VERSION ""

NS_ :

BS_:

BU_: ECU1 ECU2

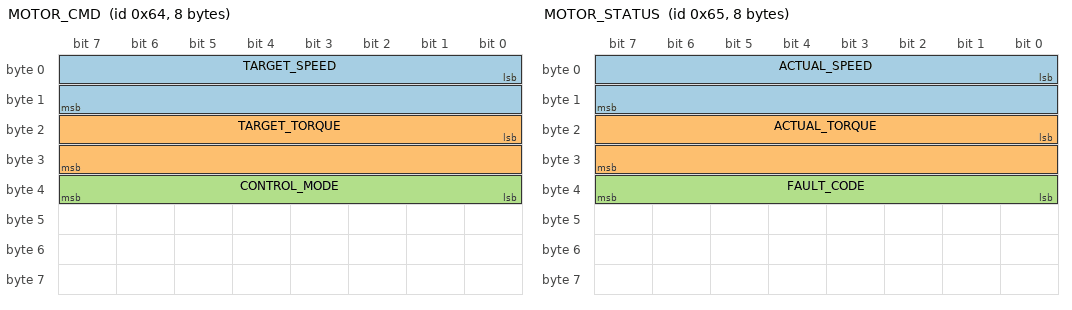
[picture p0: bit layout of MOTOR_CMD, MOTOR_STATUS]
BO_ 100 MOTOR_CMD: 8 ECU1
 SG_ TARGET_SPEED : 0|16@1- (0.1,0) [0|6000] "rpm" ECU2
 SG_ TARGET_TORQUE : 16|16@1- (0.1,0) [-100|100] "%" ECU2
 SG_ CONTROL_MODE : 32|8@1+ (1,0) [0|3] "" ECU2

BO_ 101 MOTOR_STATUS: 8 ECU2
 SG_ ACTUAL_SPEED : 0|16@1- (0.1,0) [0|6000] "rpm" ECU1
 SG_ ACTUAL_TORQUE : 16|16@1- (0.1,0) [-100|100] "%" ECU1
 SG_ FAULT_CODE : 32|8@1+ (1,0) [0|255] "" ECU1

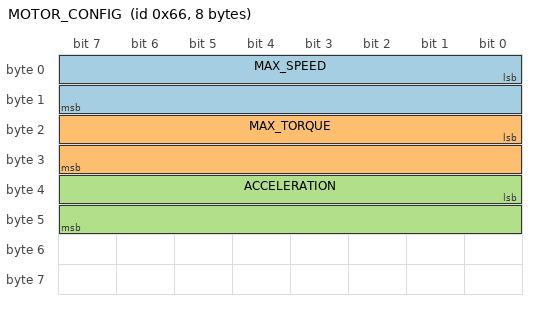
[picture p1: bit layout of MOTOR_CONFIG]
BO_ 102 MOTOR_CONFIG: 8 ECU1
 SG_ MAX_SPEED : 0|16@1- (0.1,0) [1000|6000] "rpm" ECU2
 SG_ MAX_TORQUE : 16|16@1- (0.1,0) [10|100] "%" ECU2
 SG_ ACCELERATION : 32|16@1- (0.1,0) [1|100] "rpm/s" ECU2

BA_DEF_ BO_ "CANFD_BRS" ENUM "NO","YES";
BA_DEF_ BO_ "CANFD_DataRate" INT 0 10000000;

BA_ "CANFD_BRS" BO_ 100 "YES";
BA_ "CANFD_BRS" BO_ 101 "YES";
BA_ "CANFD_BRS" BO_ 102 "YES";

BA_ "CANFD_DataRate" BO_ 100 2000000;
BA_ "CANFD_DataRate" BO_ 101 2000000;
BA_ "CANFD_DataRate" BO_ 102 2000000;

VAL_TABLE_ CONTROL_MODE 0 "TORQUE" 1 "SPEED" 2 "POSITION" 3 "STOP";
